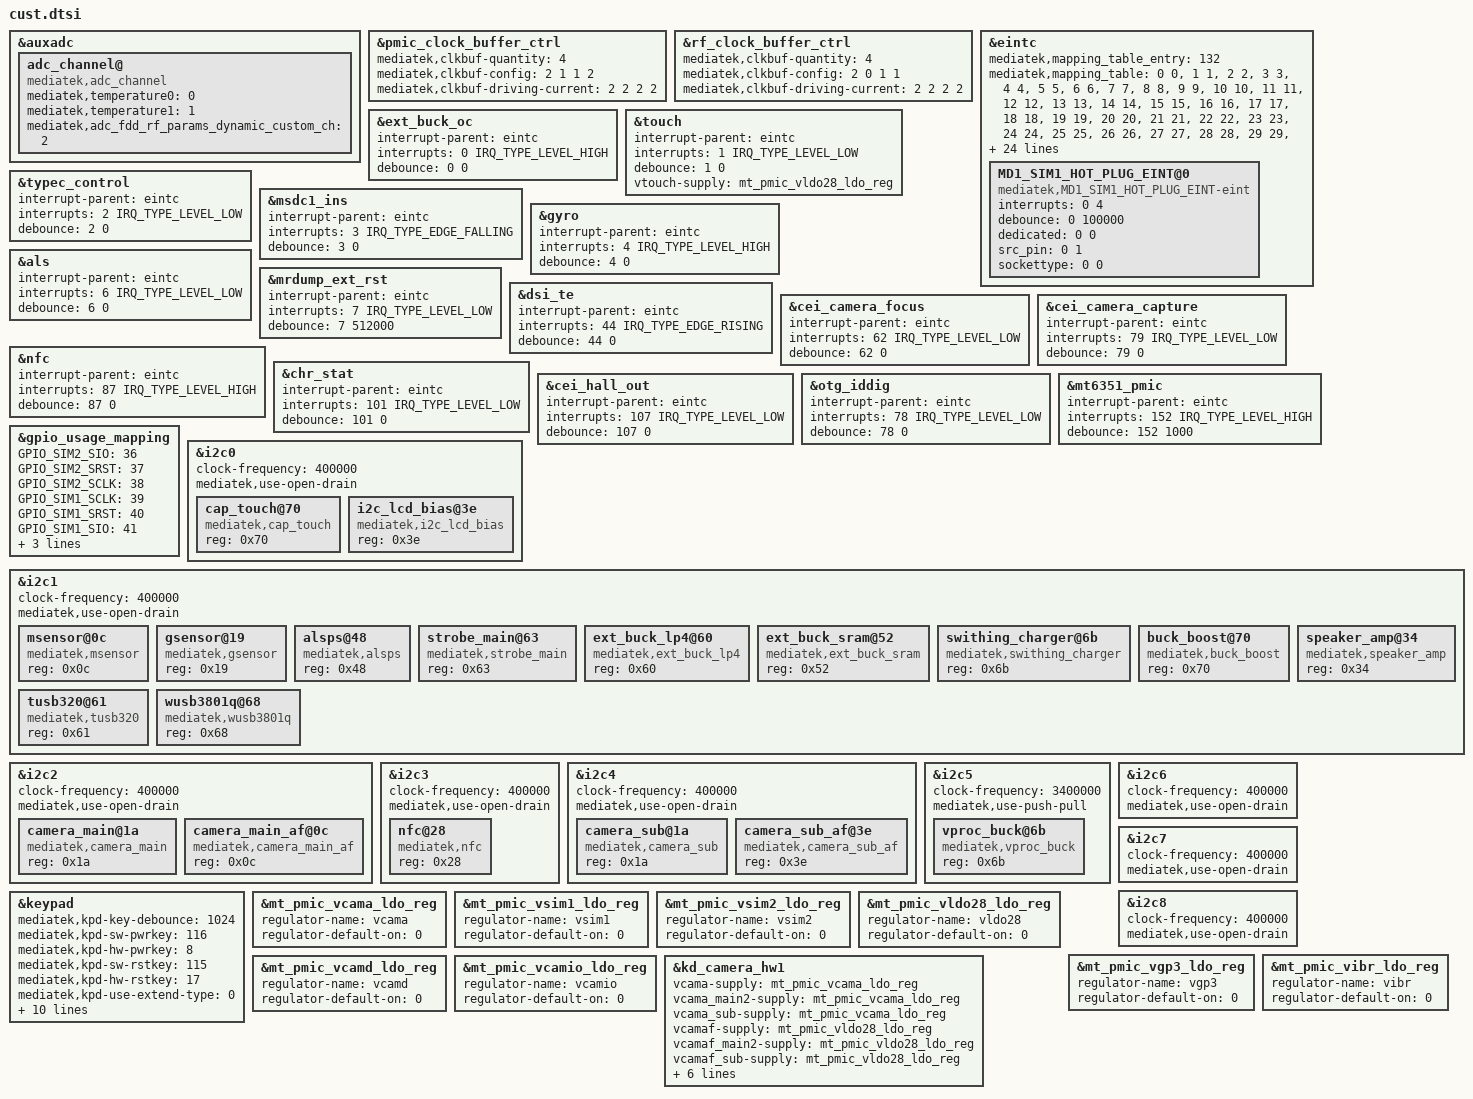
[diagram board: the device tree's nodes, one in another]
/*
 * Generated by MTK SP DrvGen Version: 3.4.160511 for MT6757.
 * 2017-06-15 13:06:14
 * Do Not Modify The File.
 * Copyright Mediatek Inc. (c) 2016.
*/

/*************************
 * ADC DTSI File
*************************/

&auxadc {
	adc_channel@ {
		compatible = "mediatek,adc_channel";
		mediatek,temperature0 = <0>;
		mediatek,temperature1 = <1>;
		mediatek,adc_fdd_rf_params_dynamic_custom_ch = <2>;
		status = "okay";
	};
};


/*************************
 * CLK_BUF DTSI File
*************************/

&pmic_clock_buffer_ctrl {
	mediatek,clkbuf-quantity = <4>;
	mediatek,clkbuf-config = <2 1 1 2>;
	mediatek,clkbuf-driving-current = <2 2 2 2>;
	status = "okay";
};

&rf_clock_buffer_ctrl {
	mediatek,clkbuf-quantity = <4>;
	mediatek,clkbuf-config = <2 0 1 1 >;
	mediatek,clkbuf-driving-current = <2 2 2 2 >;
	status = "okay";
};


/*************************
 * EINT DTSI File
*************************/

#include <dt-bindings/interrupt-controller/irq.h>
#include <dt-bindings/interrupt-controller/arm-gic.h>

&eintc {
	mediatek,mapping_table_entry = <132>;
			/* <gpio_pin, eint_pin> */
	mediatek,mapping_table = <0 0>,
					<1 1>,
					<2 2>,
					<3 3>,
					<4 4>,
					<5 5>,
					<6 6>,
					<7 7>,
					<8 8>,
					<9 9>,
					<10 10>,
					<11 11>,
					<12 12>,
					<13 13>,
					<14 14>,
					<15 15>,
					<16 16>,
					<17 17>,
					<18 18>,
					<19 19>,
					<20 20>,
					<21 21>,
					<22 22>,
					<23 23>,
					<24 24>,
					<25 25>,
					<26 26>,
					<27 27>,
					<28 28>,
					<29 29>,
					<30 30>,
					<31 31>,
					<32 32>,
					<33 33>,
					<34 34>,
					<35 35>,
					<36 36>,
					<37 37>,
					<38 38>,
					<39 39>,
					<40 40>,
					<41 41>,
					<42 42>,
					<43 43>,
					<44 44>,
					<45 45>,
					<46 46>,
					<47 47>,
					<48 48>,
					<49 49>,
					<50 50>,
					<51 51>,
					<52 52>,
					<53 53>,
					<54 54>,
					<55 55>,
					<56 56>,
					<57 57>,
					<58 58>,
					<59 59>,
					<60 60>,
					<61 61>,
					<62 62>,
					<63 63>,
					<64 64>,
					<65 65>,
					<66 66>,
					<67 67>,
					<68 68>,
					<69 69>,
					<75 75>,
					<76 76>,
					<77 77>,
					<78 78>,
					<79 79>,
					<80 80>,
					<81 81>,
					<82 82>,
					<83 83>,
					<84 84>,
					<85 85>,
					<86 86>,
					<87 87>,
					<88 88>,
					<89 89>,
					<90 90>,
					<91 91>,
					<92 92>,
					<93 93>,
					<94 94>,
					<95 95>,
					<96 96>,
					<97 97>,
					<98 98>,
					<99 99>,
					<100 100>,
					<101 101>,
					<102 102>,
					<103 103>,
					<104 104>,
					<105 105>,
					<106 106>,
					<107 107>,
					<108 108>,
					<109 109>,
					<110 110>,
					<111 111>,
					<112 112>,
					<113 113>,
					<114 114>,
					<115 115>,
					<116 116>,
					<117 117>,
					<118 118>,
					<119 119>,
					<120 120>,
					<121 121>,
					<122 122>,
					<131 131>,
					<132 132>,
					<133 133>,
					<134 134>,
					<135 135>,
					<136 136>,
					<195 153>,
					<194 152>,
					<197 155>,
					<196 154>,
					<199 157>,
					<198 156>,
					<201 159>,
					<200 158>;
	mediatek,builtin_entry = <12>;
					/* gpio, built-in func mode, built-in eint */
	mediatek,builtin_mapping = <152 1 150>, /* 1:PWRAP_SPI0_MI */
					<154 2 150>, /* 2:PWRAP_SPI0_MI */
					<11 2 144>, /* 2:IDDIG */
					<23 2 144>, /* 2:IDDIG */
					<45 6 144>, /* 6:IDDIG */
					<42 1 144>, /* 1:IDDIG */
					<0 4 144>, /* 4:IDDIG */
					<116 4 144>, /* 4:IDDIG */
					<6 3 144>, /* 3:IDDIG */
					<78 2 144>, /* 2:IDDIG */
					<152 2 152>, /* 2:PWRAP_SPI0_MO */
					<154 1 152>;};

&ext_buck_oc {
	interrupt-parent = <&eintc>;
	interrupts = <0 IRQ_TYPE_LEVEL_HIGH>;
	debounce = <0 0>;
	status = "okay";
};

&touch {
	interrupt-parent = <&eintc>;
	interrupts = <1 IRQ_TYPE_LEVEL_LOW>;
	debounce = <1 0>;
	status = "okay";
};

&typec_control {
	interrupt-parent = <&eintc>;
	interrupts = <2 IRQ_TYPE_LEVEL_LOW>;
	debounce = <2 0>;
	status = "okay";
};

&msdc1_ins {
	interrupt-parent = <&eintc>;
	interrupts = <3 IRQ_TYPE_EDGE_FALLING>;
	debounce = <3 0>;
	status = "okay";
};

&gyro {
	interrupt-parent = <&eintc>;
	interrupts = <4 IRQ_TYPE_LEVEL_HIGH>;
	debounce = <4 0>;
	status = "okay";
};

&als {
	interrupt-parent = <&eintc>;
	interrupts = <6 IRQ_TYPE_LEVEL_LOW>;
	debounce = <6 0>;
	status = "okay";
};

&mrdump_ext_rst {
	interrupt-parent = <&eintc>;
	interrupts = <7 IRQ_TYPE_LEVEL_LOW>;
	debounce = <7 512000>;
	status = "okay";
};

&dsi_te {
	interrupt-parent = <&eintc>;
	interrupts = <44 IRQ_TYPE_EDGE_RISING>;
	debounce = <44 0>;
	status = "okay";
};

&cei_camera_focus {
	interrupt-parent = <&eintc>;
	interrupts = <62 IRQ_TYPE_LEVEL_LOW>;
	debounce = <62 0>;
	status = "okay";
};

&cei_camera_capture {
	interrupt-parent = <&eintc>;
	interrupts = <79 IRQ_TYPE_LEVEL_LOW>;
	debounce = <79 0>;
	status = "okay";
};

&nfc {
	interrupt-parent = <&eintc>;
	interrupts = <87 IRQ_TYPE_LEVEL_HIGH>;
	debounce = <87 0>;
	status = "okay";
};

&chr_stat {
	interrupt-parent = <&eintc>;
	interrupts = <101 IRQ_TYPE_LEVEL_LOW>;
	debounce = <101 0>;
	status = "okay";
};

&cei_hall_out {
	interrupt-parent = <&eintc>;
	interrupts = <107 IRQ_TYPE_LEVEL_LOW>;
	debounce = <107 0>;
	status = "okay";
};

&otg_iddig {
	interrupt-parent = <&eintc>;
	interrupts = <78 IRQ_TYPE_LEVEL_LOW>;
	debounce = <78 0>;
	status = "okay";
};

&mt6351_pmic {
	interrupt-parent = <&eintc>;
	interrupts = <152 IRQ_TYPE_LEVEL_HIGH>;
	debounce = <152 1000>;
	status = "okay";
};



/*************************
 * GPIO DTSI File
*************************/

&gpio_usage_mapping {
	GPIO_SIM2_SIO = <36>;
	GPIO_SIM2_SRST = <37>;
	GPIO_SIM2_SCLK = <38>;
	GPIO_SIM1_SCLK = <39>;
	GPIO_SIM1_SRST = <40>;
	GPIO_SIM1_SIO = <41>;
	GPIO_FDD_BAND_SUPPORT_DETECT_1ST_PIN = <57>;
	GPIO_FDD_BAND_SUPPORT_DETECT_3RD_PIN = <59>;
	GPIO_FDD_BAND_SUPPORT_DETECT_2ND_PIN = <80>;
};


/*************************
 * I2C DTSI File
*************************/

&i2c0 {
	#address-cells = <1>;
	#size-cells = <0>;
	clock-frequency = <400000>;
	mediatek,use-open-drain;
	cap_touch@70 {
		compatible = "mediatek,cap_touch";
		reg = <0x70>;
		status = "okay";
	};

	i2c_lcd_bias@3e {
		compatible = "mediatek,i2c_lcd_bias";
		reg = <0x3e>;
		status = "okay";
	};

};

&i2c1 {
	#address-cells = <1>;
	#size-cells = <0>;
	clock-frequency = <400000>;
	mediatek,use-open-drain;
	msensor@0c {
		compatible = "mediatek,msensor";
		reg = <0x0c>;
		status = "okay";
	};

	gsensor@19 {
		compatible = "mediatek,gsensor";
		reg = <0x19>;
		status = "okay";
	};

	alsps@48 {
		compatible = "mediatek,alsps";
		reg = <0x48>;
		status = "okay";
	};

	strobe_main@63 {
		compatible = "mediatek,strobe_main";
		reg = <0x63>;
		status = "okay";
	};

	ext_buck_lp4@60 {
		compatible = "mediatek,ext_buck_lp4";
		reg = <0x60>;
		status = "okay";
	};

	ext_buck_sram@52 {
		compatible = "mediatek,ext_buck_sram";
		reg = <0x52>;
		status = "okay";
	};

	swithing_charger@6b {
		compatible = "mediatek,swithing_charger";
		reg = <0x6b>;
		status = "okay";
	};

	buck_boost@70 {
		compatible = "mediatek,buck_boost";
		reg = <0x70>;
		status = "okay";
	};

	speaker_amp@34 {
		compatible = "mediatek,speaker_amp";
		reg = <0x34>;
		status = "okay";
	};

	tusb320@61 {
		compatible = "mediatek,tusb320";
		reg = <0x61>;
		status = "okay";
	};

	wusb3801q@68 {
		compatible = "mediatek,wusb3801q";
		reg = <0x68>;
		status = "okay";
	};

};

&i2c2 {
	#address-cells = <1>;
	#size-cells = <0>;
	clock-frequency = <400000>;
	mediatek,use-open-drain;
	camera_main@1a {
		compatible = "mediatek,camera_main";
		reg = <0x1a>;
		status = "okay";
	};

	camera_main_af@0c {
		compatible = "mediatek,camera_main_af";
		reg = <0x0c>;
		status = "okay";
	};

};

&i2c3 {
	#address-cells = <1>;
	#size-cells = <0>;
	clock-frequency = <400000>;
	mediatek,use-open-drain;
	nfc@28 {
		compatible = "mediatek,nfc";
		reg = <0x28>;
		status = "okay";
	};

};

&i2c4 {
	#address-cells = <1>;
	#size-cells = <0>;
	clock-frequency = <400000>;
	mediatek,use-open-drain;
	camera_sub@1a {
		compatible = "mediatek,camera_sub";
		reg = <0x1a>;
		status = "okay";
	};

	camera_sub_af@3e {
		compatible = "mediatek,camera_sub_af";
		reg = <0x3e>;
		status = "okay";
	};

};

&i2c5 {
	#address-cells = <1>;
	#size-cells = <0>;
	clock-frequency = <3400000>;
	mediatek,use-push-pull;
	vproc_buck@6b {
		compatible = "mediatek,vproc_buck";
		reg = <0x6b>;
		status = "okay";
	};

};

&i2c6 {
	#address-cells = <1>;
	#size-cells = <0>;
	clock-frequency = <400000>;
	mediatek,use-open-drain;
};

&i2c7 {
	#address-cells = <1>;
	#size-cells = <0>;
	clock-frequency = <400000>;
	mediatek,use-open-drain;
};

&i2c8 {
	#address-cells = <1>;
	#size-cells = <0>;
	clock-frequency = <400000>;
	mediatek,use-open-drain;
};



/*************************
 * KPD DTSI File
*************************/

&keypad {
	mediatek,kpd-key-debounce = <1024>;
	mediatek,kpd-sw-pwrkey = <116>;
	mediatek,kpd-hw-pwrkey = <8>;
	mediatek,kpd-sw-rstkey  = <115>;
	mediatek,kpd-hw-rstkey = <17>;
	mediatek,kpd-use-extend-type = <0>;
	/*HW Keycode [0~71] -> Linux Keycode*/
	mediatek,kpd-hw-map-num = <72>;
	mediatek,kpd-hw-init-map = <0 114 0 0 0 0 0 0 0 0 0 0 0 0 0 0 0 0 0 0 0 0 0 0 0 0 0 0 0 0 0 0 0 0 0 0 0 0 0 0 0 0 0 0 0 0 0 0 0 0 0 0 0 0 0 0 0 0 0 0 0 0 0 0 0 0 0 0 0 0 0 0 >;
	mediatek,kpd-pwrkey-eint-gpio = <0>;
	mediatek,kpd-pwkey-gpio-din  = <0>;
	mediatek,kpd-hw-dl-key0 = <17>;
	mediatek,kpd-hw-dl-key1 = <1>;
	mediatek,kpd-hw-dl-key2 = <8>;
	mediatek,kpd-hw-recovery-key = <1>;
	mediatek,kpd-hw-factory-key = <17>;
	status = "okay";
};


/*************************
 * MD1_EINT DTSI File
*************************/

&eintc {
	MD1_SIM1_HOT_PLUG_EINT@0 {
		compatible = "mediatek,MD1_SIM1_HOT_PLUG_EINT-eint";
		interrupts = <0 4>;
		debounce = <0 100000>;
		dedicated = <0 0>;
		src_pin = <0 1>;
		sockettype = <0 0>;
		status = "okay";
	};

};


/*************************
 * PMIC DTSI File
*************************/

&mt_pmic_vcama_ldo_reg {
	regulator-name = "vcama";
	regulator-default-on = <0>; /* 0:skip, 1: off, 2:on */
	status = "okay";
};
&mt_pmic_vsim1_ldo_reg {
	regulator-name = "vsim1";
	regulator-default-on = <0>; /* 0:skip, 1: off, 2:on */
	status = "okay";
};
&mt_pmic_vsim2_ldo_reg {
	regulator-name = "vsim2";
	regulator-default-on = <0>; /* 0:skip, 1: off, 2:on */
	status = "okay";
};
&mt_pmic_vldo28_ldo_reg {
	regulator-name = "vldo28";
	regulator-default-on = <0>; /* 0:skip, 1: off, 2:on */
	status = "okay";
};
&mt_pmic_vgp3_ldo_reg {
	regulator-name = "vgp3";
	regulator-default-on = <0>; /* 0:skip, 1: off, 2:on */
	status = "okay";
};
&mt_pmic_vibr_ldo_reg {
	regulator-name = "vibr";
	regulator-default-on = <0>; /* 0:skip, 1: off, 2:on */
	status = "okay";
};
&mt_pmic_vcamd_ldo_reg {
	regulator-name = "vcamd";
	regulator-default-on = <0>; /* 0:skip, 1: off, 2:on */
	status = "okay";
};
&mt_pmic_vcamio_ldo_reg {
	regulator-name = "vcamio";
	regulator-default-on = <0>; /* 0:skip, 1: off, 2:on */
	status = "okay";
};

&kd_camera_hw1 {
	vcama-supply = <&mt_pmic_vcama_ldo_reg>;
	vcama_main2-supply = <&mt_pmic_vcama_ldo_reg>;
	vcama_sub-supply = <&mt_pmic_vcama_ldo_reg>;
	vcamaf-supply = <&mt_pmic_vldo28_ldo_reg>;
	vcamaf_main2-supply = <&mt_pmic_vldo28_ldo_reg>;
	vcamaf_sub-supply = <&mt_pmic_vldo28_ldo_reg>;
	vcamd_main2-supply = <&mt_pmic_vgp3_ldo_reg>;
	vcamd_sub-supply = <&mt_pmic_vgp3_ldo_reg>;
	vcamd-supply = <&mt_pmic_vcamd_ldo_reg>;
	vcamio-supply = <&mt_pmic_vcamio_ldo_reg>;
	vcamio_main2-supply = <&mt_pmic_vcamio_ldo_reg>;
	vcamio_sub-supply = <&mt_pmic_vcamio_ldo_reg>;
	status = "okay";
};

&touch {
	vtouch-supply = <&mt_pmic_vldo28_ldo_reg>;
	status = "okay";
};


/*************************
 * POWER DTSI File
*************************/



